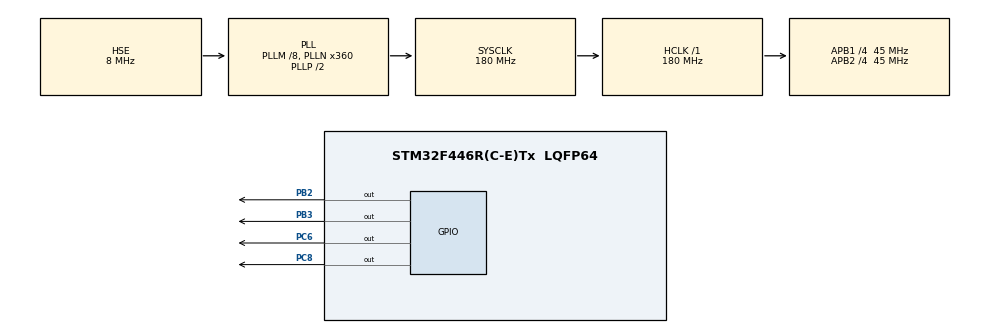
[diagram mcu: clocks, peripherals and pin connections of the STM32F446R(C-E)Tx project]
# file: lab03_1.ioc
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FREERTOS.Tasks01=defaultTask,24,128,StartDefaultTask,Default,NULL,Dynamic,NULL,NULL;myTask02,8,128,StartTask02,Default,NULL,Dynamic,NULL,NULL
FREERTOS.configUSE_NEWLIB_REENTRANT=1
Mcu.Family=STM32F4
Mcu.Name=STM32F446R(C-E)Tx
Mcu.Package=LQFP64
NVIC.PriorityGroup=NVIC_PRIORITYGROUP_4
NVIC.TIM7_IRQn=true\:15\:0\:false\:false\:true\:false\:false\:true\:true
NVIC.TimeBase=TIM7_IRQn
NVIC.TimeBaseIP=TIM7
PA13.Mode=Serial_Wire
PA13.Signal=SYS_JTMS-SWDIO
PA14.Mode=Serial_Wire
PA14.Signal=SYS_JTCK-SWCLK
PB2.Signal=GPIO_Output
PB3.Signal=GPIO_Output
PC6.Signal=GPIO_Output
PC8.Signal=GPIO_Output
PH0-OSC_IN.Mode=HSE-External-Oscillator
PH0-OSC_IN.Signal=RCC_OSC_IN
PH1-OSC_OUT.Mode=HSE-External-Oscillator
PH1-OSC_OUT.Signal=RCC_OSC_OUT
ProjectManager.HeapSize=0x200
ProjectManager.StackSize=0x400
ProjectManager.TargetToolchain=STM32CubeIDE
RCC.AHBFreq_Value=180000000
RCC.APB1CLKDivider=RCC_HCLK_DIV4
RCC.APB1Freq_Value=45000000
RCC.APB1TimFreq_Value=90000000
RCC.APB2CLKDivider=RCC_HCLK_DIV4
RCC.APB2Freq_Value=45000000
RCC.APB2TimFreq_Value=90000000
RCC.CortexFreq_Value=180000000
RCC.HCLKFreq_Value=180000000
RCC.HSE_VALUE=8000000
RCC.PLLM=8
RCC.PLLN=360
RCC.PLLSourceVirtual=RCC_PLLSOURCE_HSE
RCC.SYSCLKFreq_VALUE=180000000
RCC.SYSCLKSource=RCC_SYSCLKSOURCE_PLLCLK
RCC.USBFreq_Value=180000000
RCC.VCOOutputFreq_Value=360000000
VP_FREERTOS_VS_CMSIS_V2.Mode=CMSIS_V2
VP_SYS_VS_tim7.Mode=TIM7
board=custom

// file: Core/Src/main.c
/* USER CODE BEGIN Header */
/**
  ******************************************************************************
  * @file           : main.c
  * @brief          : Main program body
  ******************************************************************************
  * @attention
  *
  * Copyright (c) 2026 STMicroelectronics.
  * All rights reserved.
  *
  * This software is licensed under terms that can be found in the LICENSE file
  * in the root directory of this software component.
  * If no LICENSE file comes with this software, it is provided AS-IS.
  *
  ******************************************************************************
  */
/* USER CODE END Header */
#include "main.h"
#include "cmsis_os.h"

/* Definitions for defaultTask */
osThreadId_t defaultTaskHandle;
const osThreadAttr_t defaultTask_attributes = {
  .name = "defaultTask",
  .stack_size = 128 * 4,
  .priority = (osPriority_t) osPriorityNormal,
};
/* Definitions for myTask02 */
osThreadId_t myTask02Handle;
const osThreadAttr_t myTask02_attributes = {
  .name = "myTask02",
  .stack_size = 128 * 4,
  .priority = (osPriority_t) osPriorityLow,
};
/* USER CODE BEGIN PV */
GPIO_TypeDef *ledPort[4] = {GPIOB,GPIOC,GPIOC,GPIOB};
int ledGPIO[4] = {GPIO_PIN_2,GPIO_PIN_6,GPIO_PIN_8,GPIO_PIN_3};
/* USER CODE END PV */

void SystemClock_Config(void);
static void MX_GPIO_Init(void);
void StartDefaultTask(void *argument);
void StartTask02(void *argument);

int main(void)
{

  /* MCU Configuration--------------------------------------------------------*/

  /* Reset of all peripherals, Initializes the Flash interface and the Systick. */
  HAL_Init();

  /* Configure the system clock */
  SystemClock_Config();

  /* Initialize all configured peripherals */
  MX_GPIO_Init();

  /* Init scheduler */
  osKernelInitialize();

  /* Create the thread(s) */
  /* creation of defaultTask */
  defaultTaskHandle = osThreadNew(StartDefaultTask, NULL, &defaultTask_attributes);

  /* creation of myTask02 */
  myTask02Handle = osThreadNew(StartTask02, NULL, &myTask02_attributes);

  /* Start scheduler */
  osKernelStart();

  /* We should never get here as control is now taken by the scheduler */

  /* Infinite loop */
  while (1)
  {

  }
}

void SystemClock_Config(void)
{
  RCC_OscInitTypeDef RCC_OscInitStruct = {0};
  RCC_ClkInitTypeDef RCC_ClkInitStruct = {0};

  /** Configure the main internal regulator output voltage
  */
  __HAL_RCC_PWR_CLK_ENABLE();
  __HAL_PWR_VOLTAGESCALING_CONFIG(PWR_REGULATOR_VOLTAGE_SCALE1);

  /** Initializes the RCC Oscillators according to the specified parameters
  * in the RCC_OscInitTypeDef structure.
  */
  RCC_OscInitStruct.OscillatorType = RCC_OSCILLATORTYPE_HSE;
  RCC_OscInitStruct.HSEState = RCC_HSE_ON;
  RCC_OscInitStruct.PLL.PLLState = RCC_PLL_ON;
  RCC_OscInitStruct.PLL.PLLSource = RCC_PLLSOURCE_HSE;
  RCC_OscInitStruct.PLL.PLLM = 8;
  RCC_OscInitStruct.PLL.PLLN = 360;
  RCC_OscInitStruct.PLL.PLLP = RCC_PLLP_DIV2;
  RCC_OscInitStruct.PLL.PLLQ = 2;
  RCC_OscInitStruct.PLL.PLLR = 2;
  if (HAL_RCC_OscConfig(&RCC_OscInitStruct) != HAL_OK)
  {
    Error_Handler();
  }

  /** Activate the Over-Drive mode
  */
  if (HAL_PWREx_EnableOverDrive() != HAL_OK)
  {
    Error_Handler();
  }

  /** Initializes the CPU, AHB and APB buses clocks
  */
  RCC_ClkInitStruct.ClockType = RCC_CLOCKTYPE_HCLK|RCC_CLOCKTYPE_SYSCLK
                              |RCC_CLOCKTYPE_PCLK1|RCC_CLOCKTYPE_PCLK2;
  RCC_ClkInitStruct.SYSCLKSource = RCC_SYSCLKSOURCE_PLLCLK;
  RCC_ClkInitStruct.AHBCLKDivider = RCC_SYSCLK_DIV1;
  RCC_ClkInitStruct.APB1CLKDivider = RCC_HCLK_DIV4;
  RCC_ClkInitStruct.APB2CLKDivider = RCC_HCLK_DIV4;

  if (HAL_RCC_ClockConfig(&RCC_ClkInitStruct, FLASH_LATENCY_5) != HAL_OK)
  {
    Error_Handler();
  }
}

static void MX_GPIO_Init(void)
{
  GPIO_InitTypeDef GPIO_InitStruct = {0};

  /* GPIO Ports Clock Enable */
  __HAL_RCC_GPIOH_CLK_ENABLE();
  __HAL_RCC_GPIOB_CLK_ENABLE();
  __HAL_RCC_GPIOC_CLK_ENABLE();
  __HAL_RCC_GPIOA_CLK_ENABLE();

  /*Configure GPIO pin Output Level */
  HAL_GPIO_WritePin(GPIOB, GPIO_PIN_2|GPIO_PIN_3, GPIO_PIN_RESET);

  /*Configure GPIO pin Output Level */
  HAL_GPIO_WritePin(GPIOC, GPIO_PIN_6|GPIO_PIN_8, GPIO_PIN_RESET);

  /*Configure GPIO pins : PB2 PB3 */
  GPIO_InitStruct.Pin = GPIO_PIN_2|GPIO_PIN_3;
  GPIO_InitStruct.Mode = GPIO_MODE_OUTPUT_PP;
  GPIO_InitStruct.Pull = GPIO_NOPULL;
  GPIO_InitStruct.Speed = GPIO_SPEED_FREQ_LOW;
  HAL_GPIO_Init(GPIOB, &GPIO_InitStruct);

  /*Configure GPIO pins : PC6 PC8 */
  GPIO_InitStruct.Pin = GPIO_PIN_6|GPIO_PIN_8;
  GPIO_InitStruct.Mode = GPIO_MODE_OUTPUT_PP;
  GPIO_InitStruct.Pull = GPIO_NOPULL;
  GPIO_InitStruct.Speed = GPIO_SPEED_FREQ_LOW;
  HAL_GPIO_Init(GPIOC, &GPIO_InitStruct);

}

void StartDefaultTask(void *argument)
{
  /* USER CODE BEGIN 5 */
  /* Infinite loop */
  for(;;)
  {
	HAL_GPIO_WritePin(ledPort[0],ledGPIO[0],1);
	HAL_GPIO_WritePin(ledPort[1],ledGPIO[1],0);
	osDelay(200);
	HAL_GPIO_WritePin(ledPort[0],ledGPIO[0],0);
	HAL_GPIO_WritePin(ledPort[1],ledGPIO[1],1);
    osDelay(200);
  }
  /* USER CODE END 5 */
}

void StartTask02(void *argument)
{
  /* USER CODE BEGIN StartTask02 */
  /* Infinite loop */
  for(;;)
  {
	HAL_GPIO_WritePin(ledPort[2],ledGPIO[2],1);
	HAL_GPIO_WritePin(ledPort[3],ledGPIO[3],0);
	osDelay(100);
	HAL_GPIO_WritePin(ledPort[2],ledGPIO[2],0);
	HAL_GPIO_WritePin(ledPort[3],ledGPIO[3],1);
	osDelay(100);
  }
  /* USER CODE END StartTask02 */
}

void HAL_TIM_PeriodElapsedCallback(TIM_HandleTypeDef *htim)
{
  if (htim->Instance == TIM7)
  {
    HAL_IncTick();
  }
}

void Error_Handler(void)
{
  __disable_irq();
  while (1)
  {
  }
}
